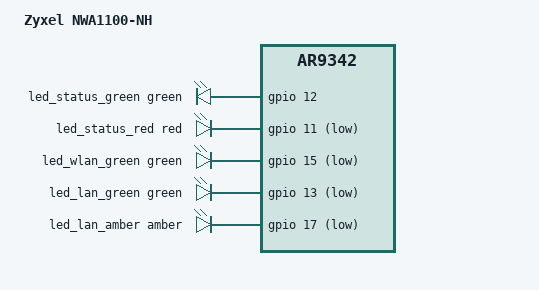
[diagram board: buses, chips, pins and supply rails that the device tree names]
// SPDX-License-Identifier: GPL-2.0-or-later OR MIT

#include <dt-bindings/leds/common.h>

#include "ar9342_zyxel_nwa11xx.dtsi"

/ {
	compatible = "zyxel,nwa1100-nh", "qca,ar9342";
	model = "Zyxel NWA1100-NH";

	aliases {
		label-mac-device = &eth0;
		led-boot = &led_status_green;
		led-failsafe = &led_status_red;
		led-running = &led_status_green;
		led-upgrade = &led_status_red;
	};
	leds {
		compatible = "gpio-leds";

		led_status_green: status_green {
			function = LED_FUNCTION_STATUS;
			color = <LED_COLOR_ID_GREEN>;
			gpios = <&gpio 12 GPIO_ACTIVE_HIGH>;
			default-state = "on";
		};

		led_status_red: status_red {
			function = LED_FUNCTION_STATUS;
			color = <LED_COLOR_ID_RED>;
			gpios = <&gpio 11 GPIO_ACTIVE_LOW>;
		};

		led_wlan_green: wlan_green {
			function = LED_FUNCTION_WLAN;
			color = <LED_COLOR_ID_GREEN>;
			gpios = <&gpio 15 GPIO_ACTIVE_LOW>;
			linux,default-trigger = "phy0tpt";
		};

		led_lan_green: lan_green {
			function = LED_FUNCTION_LAN;
			color = <LED_COLOR_ID_GREEN>;
			gpios = <&gpio 13 GPIO_ACTIVE_LOW>;
		};

		led_lan_amber: lan_amber {
			function = LED_FUNCTION_LAN;
			color = <LED_COLOR_ID_AMBER>;
			gpios = <&gpio 17 GPIO_ACTIVE_LOW>;
		};
	};
};
